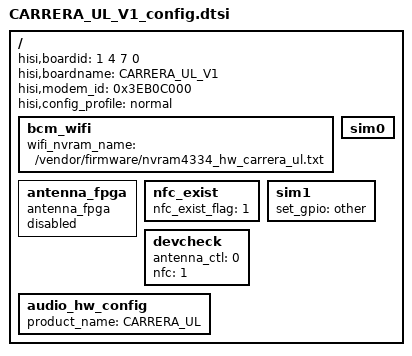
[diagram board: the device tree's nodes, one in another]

/**
 * Huawei Ltd.
 * PhosphorV660
 */


/include/ "fastboot.dtsi"
/include/ "CARRERA_TUGL_V1_config.dtsi"
/include/ "CARRERA_UL_V1_pin.dtsi"
/include/ "CARRERA_UL_V1_hi6402_pin.dtsi"
/include/ "CARRERA_UL_V1_modem_pin.dtsi"
///include/ "CARRERA_UL_V1_charger.dtsi"
///include/ "CARRERA_UL_V1_pmic.dtsi"
///include/ "CARRERA_UL_V1_gpio_logic.dtsi"

/ {
	hisi,boardid = <1 4 7 0 >;
	hisi,boardname = "CARRERA_UL_V1";
	hisi,modem_id = <0x3EB0C000>;
	hisi,config_profile = "normal";

	bcm_wifi {
		wifi_nvram_name = "/vendor/firmware/nvram4334_hw_carrera_ul.txt";
	};
	antenna_fpga{
		compatible = "antenna_fpga";
		status = "disabled";
	};
	nfc_exist {
		nfc_exist_flag = "1";
		status = "ok";
	};
	sim0 {
		status = "ok";
	};
	sim1 {
		status = "ok";
		set_gpio="other";
	};
	devcheck: devcheck {
		antenna_ctl = <0>;
		nfc = <1>;
	};
	audio_hw_config {
		product_name = "CARRERA_UL";
		status = "ok";
	};
};
